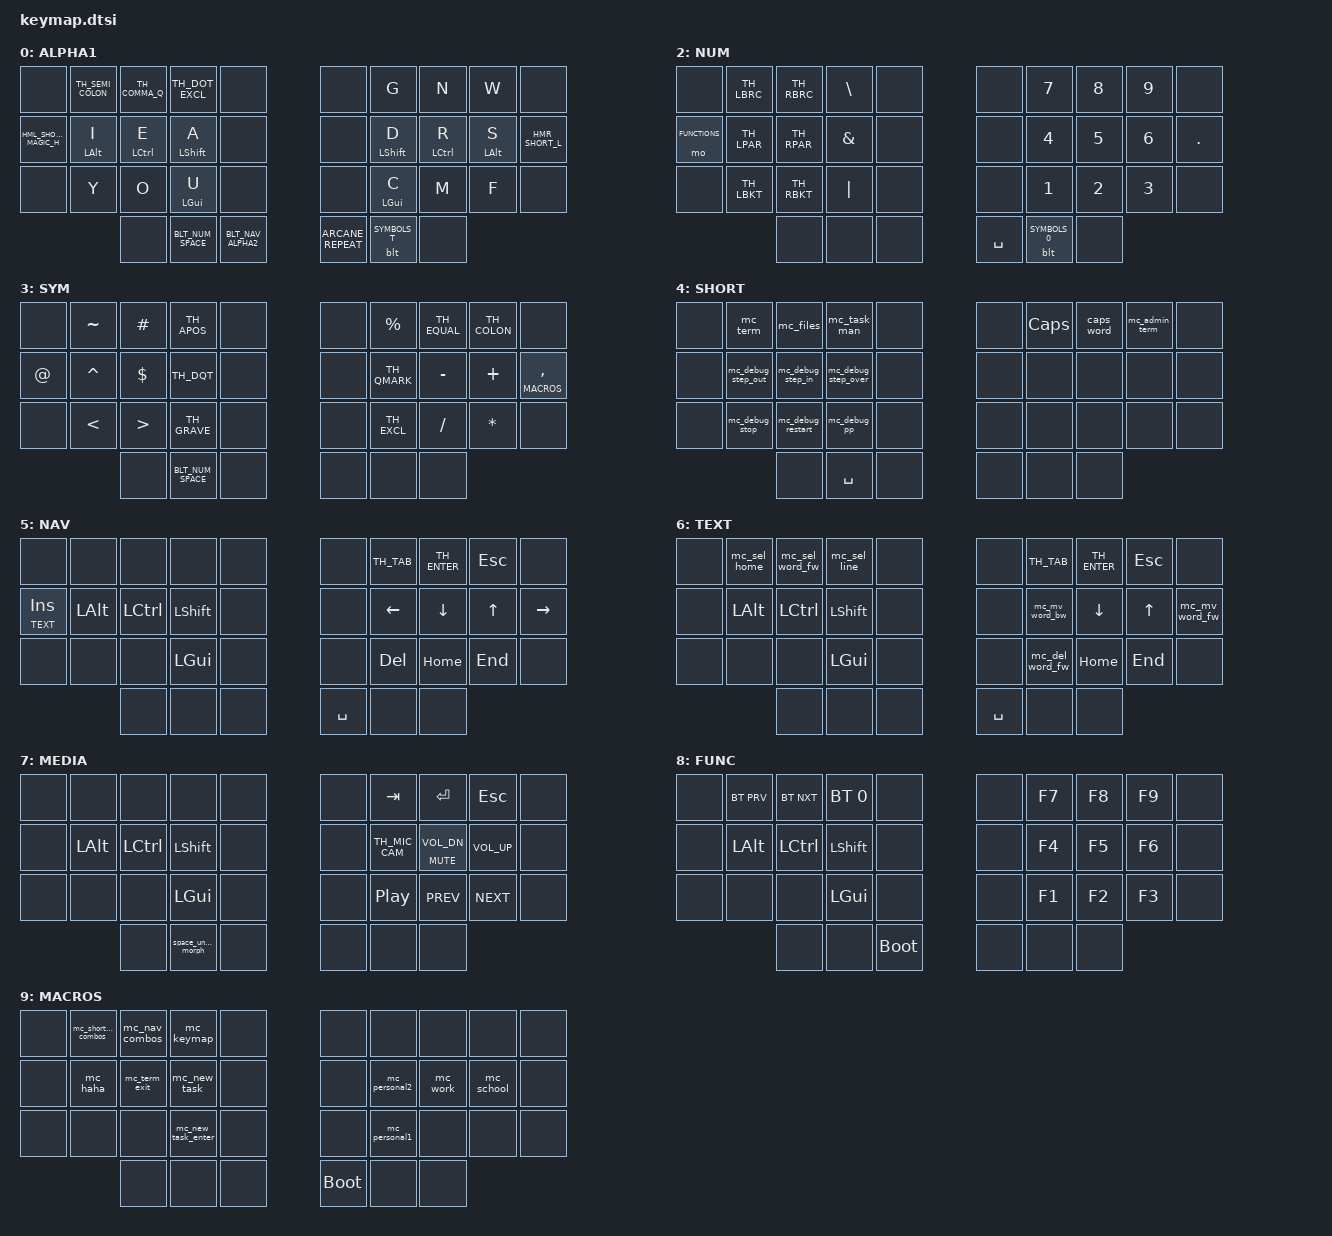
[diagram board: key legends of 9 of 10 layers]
#include "includes.h"

/   {
        keymap {
                compatible = "zmk,keymap";

                alpha1_layer {
                     display-name = "ALPHA1";
                     bindings = <
    &none               TH_SEMI_COLON       TH_COMMA_Q          TH_DOT_EXCL         &none               &none               &kp G               &kp N               &kp W               &none
    HML_SHORT_MAGIC_H   &hml LALT I         &hml LCTRL E        &hml LSHFT A        &none               &none               &hmr LSHFT D        &hmr LCTRL R        &hmr LALT S         HMR_SHORT_L
    &none               &kp Y               &kp O               &hml LGUI U         &none               &none               &hmr LGUI C         &kp M               &kp F               &none
                                            &none               BLT_NUM_SPACE       BLT_NAV_ALPHA2      ARCANE_REPEAT       &blt SYMBOLS T      &none
                        >;
                };

                alpha2_layer {
                     display-name = "ALPHA2";
                     bindings = <
    &none               TH_COLON_SEMI       TH_Q_COMMA          TH_EXCL_DOT         &none               &none               &kp B               &kp J               &kp K               &none
    &kp X               HML_ACC_I_CIRC      HML_ACC_E_AIGU      HML_ACC_A_GRAVE     &none               &none               &hmr LSHFT  P       &hmr LCTRL RA(SQT)  &hmr LALT RA(GRAVE) &kp V
    &none               &kp Q               &acc_o_circ         HML_ACC_U_CIRC      &none               &none               HMR_ACC_C_CEDILLE   &kp RA(CARET)       &kp RA(DQT)         &none
                                            &none               &space_under_morph  &none               &none               &kp MINUS           &none
                        >;
                };

                numbers_layer {
                     display-name = "NUM";
                     bindings = <
    &none               TH_LBRC             TH_RBRC             &kp BSLH            &none               &none               &kp N7              &kp N8              &kp N9              &none
    &mo FUNCTIONS       TH_LPAR             TH_RPAR             &kp AMPS            &none               &none               &kp N4              &kp N5              &kp N6              &kp DOT
    &none               TH_LBKT             TH_RBKT             &kp PIPE            &none               &none               &kp N1              &kp N2              &kp N3              &none
                                            &none               &none               &none               &kp SPACE           &blt SYMBOLS N0     &none
                        >;
                };

                symbols_layer {
                     display-name = "SYM";
                     bindings = <
    &none               &kp TILDE           &kp POUND           TH_APOS             &none               &none               &kp PERCENT         TH_EQUAL            TH_COLON            &none
    &kp AT              &kp CARET           &kp DOLLAR          TH_DQT              &none               &none               TH_QMARK            &kp MINUS           &kp PLUS            &lt MACROS COMMA
    &none               &kp LT              &kp GT              TH_GRAVE            &none               &none               TH_EXCL             &kp FSLH            &kp STAR            &none
                                            &none               BLT_NUM_SPACE       &none               &none               &none               &none
                        >;
                };

                shortcuts_layer {
                     display-name = "SHORT";
                     bindings = <
    &none               &mc_term            &mc_files           &mc_task_man        &none               &none               &kp CAPSLOCK        &caps_word          &mc_admin_term      &none
    &none               &mc_debug_step_out  &mc_debug_step_in   &mc_debug_step_over &none               &none               &none               &none               &none               &none
    &none               &mc_debug_stop      &mc_debug_restart   &mc_debug_pp        &none               &none               &none               &none               &none               &none
                                            &none               &kp SPACE           &none               &none               &none               &none
                        >;
                };

                nav_layer {
                     display-name = "NAV";
                     bindings = <
    &none               &none               &none               &none               &none               &none               TH_TAB              TH_ENTER            &kp ESC             &none
    &lt TEXT INS        &kp LALT            &kp LCTRL           &kp LSHFT           &none               &none               &kp LEFT            &kp DOWN            &kp UP              &kp RIGHT
    &none               &none               &none               &kp LGUI            &none               &none               &kp DEL             &kp HOME            &kp END             &none
                                            &none               &none               &none               &kp SPACE           &none               &none
                        >;
                };

                text_layer {
                     display-name = "TEXT";
                     bindings = <
    &none               &mc_sel_home        &mc_sel_word_fw     &mc_sel_line        &none               &none               TH_TAB              TH_ENTER            &kp ESC             &none
    &none               &kp LALT            &kp LCTRL           &kp LSHFT           &none               &none               &mc_mv_word_bw      &kp DOWN            &kp UP              &mc_mv_word_fw
    &none               &none               &none               &kp LGUI            &none               &none               &mc_del_word_fw     &kp HOME            &kp END             &none
                                            &none               &none               &none               &kp SPACE           &none               &none
                        >;
                };

                media_layer {
                     display-name = "MEDIA";
                     bindings = <
    &none               &none               &none               &none               &none               &none               &kp TAB             &kp ENTER           &kp ESC             &none
    &none               &kp LALT            &kp LCTRL           &kp LSHFT           &none               &none               TH_MIC_CAM          &mt C_MUTE C_VOL_DN &kp C_VOL_UP        &none
    &none               &none               &none               &kp LGUI            &none               &none               &kp C_PP            &kp C_PREV          &kp C_NEXT          &none
                                            &none               &space_under_morph  &none               &none               &none               &none
                        >;
                };

                functions_layer {
                     display-name = "FUNC";
                     bindings = <
    &none               &bt BT_PRV          &bt BT_NXT          &bt BT_SEL 0        &none               &none               &kp F7              &kp F8              &kp F9               &none
    &none               &kp LALT            &kp LCTRL           &kp LSHFT           &none               &none               &kp F4              &kp F5              &kp F6               &none
    &none               &none               &none               &kp LGUI            &none               &none               &kp F1              &kp F2              &kp F3               &none
                                            &none               &none               &bootloader         &none               &none               &none
                        >;
                };

                macros_layer {
                     display-name = "MACROS";
                     bindings = <
    &none               &mc_shortcut_combos &mc_nav_combos      &mc_keymap          &none               &none               &none               &none               &none               &none
    &none               &mc_haha            &mc_term_exit       &mc_new_task        &none               &none               &mc_personal2       &mc_work            &mc_school          &none
    &none               &none               &none               &mc_new_task_enter  &none               &none               &mc_personal1       &none               &none               &none
                                            &none               &none               &none               &bootloader         &none               &none
                        >;
                };

    //             template_layer {
    //                  display-name = "TEMPLATE";
    //                  bindings = <
    // &none               &none               &none               &none               &none               &none               &none               &none               &none               &none
    // &none               &none               &none               &none               &none               &none               &none               &none               &none               &none
    // &none               &none               &none               &none               &none               &none               &none               &none               &none               &none
    //                                         &none               &none               &none               &none               &none               &none
    //                     >;
    //             };

        };
};
